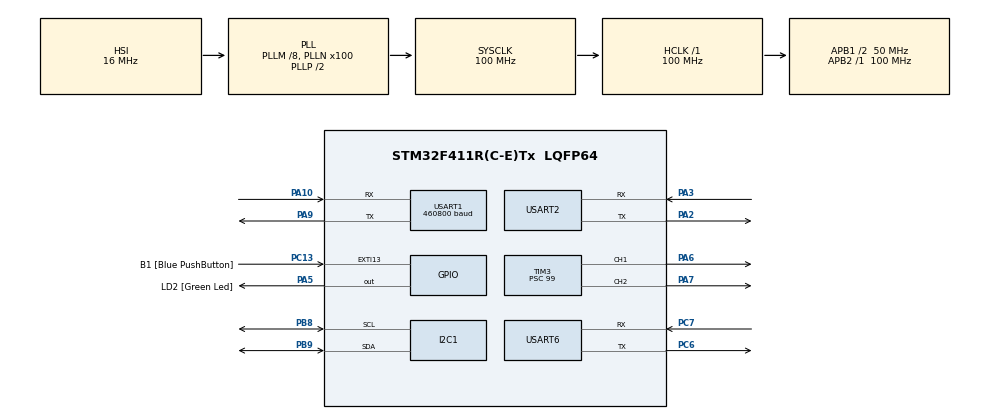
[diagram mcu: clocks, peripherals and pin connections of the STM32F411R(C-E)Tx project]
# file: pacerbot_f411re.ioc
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Dma.Request0=USART1_RX
Dma.Request1=USART1_TX
Dma.Request2=USART6_RX
Dma.Request3=USART6_TX
Dma.USART1_RX.0.Direction=DMA_PERIPH_TO_MEMORY
Dma.USART1_RX.0.FIFOMode=DMA_FIFOMODE_DISABLE
Dma.USART1_RX.0.Instance=DMA2_Stream2
Dma.USART1_RX.0.MemDataAlignment=DMA_MDATAALIGN_BYTE
Dma.USART1_RX.0.MemInc=DMA_MINC_ENABLE
Dma.USART1_RX.0.Mode=DMA_CIRCULAR
Dma.USART1_RX.0.PeriphDataAlignment=DMA_PDATAALIGN_BYTE
Dma.USART1_RX.0.PeriphInc=DMA_PINC_DISABLE
Dma.USART1_RX.0.Priority=DMA_PRIORITY_HIGH
Dma.USART1_TX.1.Direction=DMA_MEMORY_TO_PERIPH
Dma.USART1_TX.1.FIFOMode=DMA_FIFOMODE_DISABLE
Dma.USART1_TX.1.Instance=DMA2_Stream7
Dma.USART1_TX.1.MemDataAlignment=DMA_MDATAALIGN_BYTE
Dma.USART1_TX.1.MemInc=DMA_MINC_ENABLE
Dma.USART1_TX.1.Mode=DMA_NORMAL
Dma.USART1_TX.1.PeriphDataAlignment=DMA_PDATAALIGN_BYTE
Dma.USART1_TX.1.PeriphInc=DMA_PINC_DISABLE
Dma.USART1_TX.1.Priority=DMA_PRIORITY_LOW
Dma.USART6_RX.2.Direction=DMA_PERIPH_TO_MEMORY
Dma.USART6_RX.2.FIFOMode=DMA_FIFOMODE_DISABLE
Dma.USART6_RX.2.Instance=DMA2_Stream1
Dma.USART6_RX.2.MemDataAlignment=DMA_MDATAALIGN_BYTE
Dma.USART6_RX.2.MemInc=DMA_MINC_ENABLE
Dma.USART6_RX.2.Mode=DMA_CIRCULAR
Dma.USART6_RX.2.PeriphDataAlignment=DMA_PDATAALIGN_BYTE
Dma.USART6_RX.2.PeriphInc=DMA_PINC_DISABLE
Dma.USART6_RX.2.Priority=DMA_PRIORITY_MEDIUM
Dma.USART6_TX.3.Direction=DMA_MEMORY_TO_PERIPH
Dma.USART6_TX.3.FIFOMode=DMA_FIFOMODE_DISABLE
Dma.USART6_TX.3.Instance=DMA2_Stream6
Dma.USART6_TX.3.MemDataAlignment=DMA_MDATAALIGN_BYTE
Dma.USART6_TX.3.MemInc=DMA_MINC_ENABLE
Dma.USART6_TX.3.Mode=DMA_NORMAL
Dma.USART6_TX.3.PeriphDataAlignment=DMA_PDATAALIGN_BYTE
Dma.USART6_TX.3.PeriphInc=DMA_PINC_DISABLE
Dma.USART6_TX.3.Priority=DMA_PRIORITY_LOW
FREERTOS.Tasks01=defaultTask,8,1024,StartDefaultTask,Default,NULL,Dynamic,NULL,NULL
FREERTOS.configENABLE_FPU=1
FREERTOS.configTOTAL_HEAP_SIZE=64000
Mcu.Family=STM32F4
Mcu.Name=STM32F411R(C-E)Tx
Mcu.Package=LQFP64
NVIC.DMA2_Stream1_IRQn=true\:5\:0\:false\:false\:true\:true\:false\:true\:true
NVIC.DMA2_Stream2_IRQn=true\:5\:0\:false\:false\:true\:true\:false\:true\:true
NVIC.DMA2_Stream6_IRQn=true\:5\:0\:false\:false\:true\:true\:false\:true\:true
NVIC.DMA2_Stream7_IRQn=true\:5\:0\:false\:false\:true\:true\:false\:true\:true
NVIC.PriorityGroup=NVIC_PRIORITYGROUP_4
NVIC.TIM1_UP_TIM10_IRQn=true\:15\:0\:false\:false\:true\:false\:false\:true\:true
NVIC.TimeBase=TIM1_UP_TIM10_IRQn
NVIC.TimeBaseIP=TIM1
NVIC.USART1_IRQn=true\:5\:0\:false\:false\:true\:true\:true\:true\:true
NVIC.USART2_IRQn=true\:5\:0\:false\:false\:true\:true\:true\:true\:true
NVIC.USART6_IRQn=true\:5\:0\:false\:false\:true\:true\:true\:true\:true
PA10.Mode=Asynchronous
PA10.Signal=USART1_RX
PA13.GPIO_Label=TMS
PA13.Mode=Serial_Wire
PA13.Signal=SYS_JTMS-SWDIO
PA14.GPIO_Label=TCK
PA14.Mode=Serial_Wire
PA14.Signal=SYS_JTCK-SWCLK
PA2.Mode=Asynchronous
PA2.Signal=USART2_TX
PA3.Mode=Asynchronous
PA3.Signal=USART2_RX
PA5.GPIO_Label=LD2 [Green Led]
PA5.Signal=GPIO_Output
PA6.Signal=S_TIM3_CH1
PA7.Signal=S_TIM3_CH2
PA9.Mode=Asynchronous
PA9.Signal=USART1_TX
PB3.GPIO_Label=SWO
PB3.Signal=SYS_JTDO-SWO
PB8.Mode=I2C
PB8.Signal=I2C1_SCL
PB9.Mode=I2C
PB9.Signal=I2C1_SDA
PC13-ANTI_TAMP.GPIO_Label=B1 [Blue PushButton]
PC13-ANTI_TAMP.GPIO_ModeDefaultEXTI=GPIO_MODE_IT_FALLING
PC13-ANTI_TAMP.Signal=GPXTI13
PC14-OSC32_IN.Mode=LSE-External-Oscillator
PC14-OSC32_IN.Signal=RCC_OSC32_IN
PC15-OSC32_OUT.Mode=LSE-External-Oscillator
PC15-OSC32_OUT.Signal=RCC_OSC32_OUT
PC6.Mode=Asynchronous
PC6.Signal=USART6_TX
PC7.Mode=Asynchronous
PC7.Signal=USART6_RX
PH0\ -\ OSC_IN.Mode=HSE-External-Clock-Source
PH0\ -\ OSC_IN.Signal=RCC_OSC_IN
PH1\ -\ OSC_OUT.Mode=HSE-External-Clock-Source
PH1\ -\ OSC_OUT.Signal=RCC_OSC_OUT
ProjectManager.HeapSize=0x200
ProjectManager.StackSize=0x400
ProjectManager.TargetToolchain=CMake
RCC.48MHZClocksFreq_Value=50000000
RCC.AHBFreq_Value=100000000
RCC.APB1CLKDivider=RCC_HCLK_DIV2
RCC.APB1Freq_Value=50000000
RCC.APB1TimFreq_Value=100000000
RCC.APB2Freq_Value=100000000
RCC.APB2TimFreq_Value=100000000
RCC.CortexFreq_Value=100000000
RCC.FLatency-AdvancedSettings=FLASH_LATENCY_3
RCC.HCLKFreq_Value=100000000
RCC.HSE_VALUE=8000000
RCC.HSI_VALUE=16000000
RCC.PLLM=8
RCC.PLLN=100
RCC.SYSCLKFreq_VALUE=100000000
RCC.SYSCLKSource=RCC_SYSCLKSOURCE_PLLCLK
RCC.VCOOutputFreq_Value=200000000
SH.S_TIM3_CH1.0=TIM3_CH1,PWM Generation1 CH1
SH.S_TIM3_CH2.0=TIM3_CH2,PWM Generation2 CH2
TIM3.AutoReloadPreload=TIM_AUTORELOAD_PRELOAD_ENABLE
TIM3.Channel-PWM\ Generation1\ CH1=TIM_CHANNEL_1
TIM3.Channel-PWM\ Generation2\ CH2=TIM_CHANNEL_2
TIM3.Period=19999
TIM3.Prescaler=99
TIM3.Pulse-PWM\ Generation1\ CH1=1500
USART1.BaudRate=460800
USART1.VirtualMode=VM_ASYNC
USART2.VirtualMode=VM_ASYNC
USART6.VirtualMode=VM_ASYNC
VP_FREERTOS_VS_CMSIS_V2.Mode=CMSIS_V2
VP_SYS_VS_tim1.Mode=TIM1
board=NUCLEO-F411RE

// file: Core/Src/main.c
/* USER CODE BEGIN Header */
/**
 ******************************************************************************
 * @file           : main.c
 * @brief          : Main program body
 ******************************************************************************
 * @attention
 *
 * Copyright (c) 2025 STMicroelectronics.
 * All rights reserved.
 *
 * This software is licensed under terms that can be found in the LICENSE file
 * in the root directory of this software component.
 * If no LICENSE file comes with this software, it is provided AS-IS.
 *
 ******************************************************************************
 */
/* USER CODE END Header */
#include "main.h"
#include "cmsis_os.h"

/* USER CODE BEGIN Includes */
#include "app/app_main.h"

#include <stdio.h>
#include <string.h>
#include <unistd.h>
/* USER CODE END Includes */

/* USER CODE BEGIN PD */
#define IMU_ADDRESS  0x68
#define WHO_AM_I     0x75
#define ACCEL_CONFIG 0x1C
#define ACCEL_XOUT_H 0x3B
#define ACCEL_YOUT_H 0x3D
#define GYRO_XOUT_H  0x43

/* USER CODE END PD */

I2C_HandleTypeDef hi2c1;

TIM_HandleTypeDef htim3;

UART_HandleTypeDef huart1;
UART_HandleTypeDef huart2;
UART_HandleTypeDef huart6;
DMA_HandleTypeDef hdma_usart1_rx;
DMA_HandleTypeDef hdma_usart1_tx;
DMA_HandleTypeDef hdma_usart6_rx;
DMA_HandleTypeDef hdma_usart6_tx;

/* Definitions for defaultTask */
osThreadId_t defaultTaskHandle;
const osThreadAttr_t defaultTask_attributes = {
  .name = "defaultTask",
  .stack_size = 1024 * 4,
  .priority = (osPriority_t) osPriorityLow,
};

void SystemClock_Config(void);
static void MX_GPIO_Init(void);
static void MX_DMA_Init(void);
static void MX_I2C1_Init(void);
static void MX_USART1_UART_Init(void);
static void MX_USART2_UART_Init(void);
static void MX_TIM3_Init(void);
static void MX_USART6_UART_Init(void);
void StartDefaultTask(void *argument);

int main(void)
{

  /* MCU Configuration--------------------------------------------------------*/

  /* Reset of all peripherals, Initializes the Flash interface and the Systick. */
  HAL_Init();

  /* Configure the system clock */
  SystemClock_Config();

  /* Initialize all configured peripherals */
  MX_GPIO_Init();
  MX_DMA_Init();
  MX_I2C1_Init();
  MX_USART1_UART_Init();
  MX_USART2_UART_Init();
  MX_TIM3_Init();
  MX_USART6_UART_Init();
  /* USER CODE BEGIN 2 */
    setvbuf(stdout, NULL, _IONBF, 0);
    printf("BOOT: hello on USART2\n");

  /* USER CODE END 2 */

  /* Init scheduler */
  osKernelInitialize();

  /* Create the thread(s) */
  /* creation of defaultTask */
  defaultTaskHandle = osThreadNew(StartDefaultTask, NULL, &defaultTask_attributes);

  /* Start scheduler */
  osKernelStart();

  /* We should never get here as control is now taken by the scheduler */

  /* Infinite loop */
    while (1) {

    }
}

void SystemClock_Config(void)
{
  RCC_OscInitTypeDef RCC_OscInitStruct = {0};
  RCC_ClkInitTypeDef RCC_ClkInitStruct = {0};

  /** Configure the main internal regulator output voltage
  */
  __HAL_RCC_PWR_CLK_ENABLE();
  __HAL_PWR_VOLTAGESCALING_CONFIG(PWR_REGULATOR_VOLTAGE_SCALE1);

  /** Initializes the RCC Oscillators according to the specified parameters
  * in the RCC_OscInitTypeDef structure.
  */
  RCC_OscInitStruct.OscillatorType = RCC_OSCILLATORTYPE_HSI;
  RCC_OscInitStruct.HSIState = RCC_HSI_ON;
  RCC_OscInitStruct.HSICalibrationValue = RCC_HSICALIBRATION_DEFAULT;
  RCC_OscInitStruct.PLL.PLLState = RCC_PLL_ON;
  RCC_OscInitStruct.PLL.PLLSource = RCC_PLLSOURCE_HSI;
  RCC_OscInitStruct.PLL.PLLM = 8;
  RCC_OscInitStruct.PLL.PLLN = 100;
  RCC_OscInitStruct.PLL.PLLP = RCC_PLLP_DIV2;
  RCC_OscInitStruct.PLL.PLLQ = 4;
  if (HAL_RCC_OscConfig(&RCC_OscInitStruct) != HAL_OK)
  {
    Error_Handler();
  }

  /** Initializes the CPU, AHB and APB buses clocks
  */
  RCC_ClkInitStruct.ClockType = RCC_CLOCKTYPE_HCLK|RCC_CLOCKTYPE_SYSCLK
                              |RCC_CLOCKTYPE_PCLK1|RCC_CLOCKTYPE_PCLK2;
  RCC_ClkInitStruct.SYSCLKSource = RCC_SYSCLKSOURCE_PLLCLK;
  RCC_ClkInitStruct.AHBCLKDivider = RCC_SYSCLK_DIV1;
  RCC_ClkInitStruct.APB1CLKDivider = RCC_HCLK_DIV2;
  RCC_ClkInitStruct.APB2CLKDivider = RCC_HCLK_DIV1;

  if (HAL_RCC_ClockConfig(&RCC_ClkInitStruct, FLASH_LATENCY_3) != HAL_OK)
  {
    Error_Handler();
  }
}

static void MX_I2C1_Init(void)
{

  hi2c1.Instance = I2C1;
  hi2c1.Init.ClockSpeed = 100000;
  hi2c1.Init.DutyCycle = I2C_DUTYCYCLE_2;
  hi2c1.Init.OwnAddress1 = 0;
  hi2c1.Init.AddressingMode = I2C_ADDRESSINGMODE_7BIT;
  hi2c1.Init.DualAddressMode = I2C_DUALADDRESS_DISABLE;
  hi2c1.Init.OwnAddress2 = 0;
  hi2c1.Init.GeneralCallMode = I2C_GENERALCALL_DISABLE;
  hi2c1.Init.NoStretchMode = I2C_NOSTRETCH_DISABLE;
  if (HAL_I2C_Init(&hi2c1) != HAL_OK)
  {
    Error_Handler();
  }

}

static void MX_TIM3_Init(void)
{

  TIM_MasterConfigTypeDef sMasterConfig = {0};
  TIM_OC_InitTypeDef sConfigOC = {0};

  htim3.Instance = TIM3;
  htim3.Init.Prescaler = 99;
  htim3.Init.CounterMode = TIM_COUNTERMODE_UP;
  htim3.Init.Period = 19999;
  htim3.Init.ClockDivision = TIM_CLOCKDIVISION_DIV1;
  htim3.Init.AutoReloadPreload = TIM_AUTORELOAD_PRELOAD_ENABLE;
  if (HAL_TIM_PWM_Init(&htim3) != HAL_OK)
  {
    Error_Handler();
  }
  sMasterConfig.MasterOutputTrigger = TIM_TRGO_RESET;
  sMasterConfig.MasterSlaveMode = TIM_MASTERSLAVEMODE_DISABLE;
  if (HAL_TIMEx_MasterConfigSynchronization(&htim3, &sMasterConfig) != HAL_OK)
  {
    Error_Handler();
  }
  sConfigOC.OCMode = TIM_OCMODE_PWM1;
  sConfigOC.Pulse = 1500;
  sConfigOC.OCPolarity = TIM_OCPOLARITY_HIGH;
  sConfigOC.OCFastMode = TIM_OCFAST_DISABLE;
  if (HAL_TIM_PWM_ConfigChannel(&htim3, &sConfigOC, TIM_CHANNEL_1) != HAL_OK)
  {
    Error_Handler();
  }
  sConfigOC.Pulse = 0;
  if (HAL_TIM_PWM_ConfigChannel(&htim3, &sConfigOC, TIM_CHANNEL_2) != HAL_OK)
  {
    Error_Handler();
  }
  HAL_TIM_MspPostInit(&htim3);

}

static void MX_USART1_UART_Init(void)
{

  huart1.Instance = USART1;
  huart1.Init.BaudRate = 460800;
  huart1.Init.WordLength = UART_WORDLENGTH_8B;
  huart1.Init.StopBits = UART_STOPBITS_1;
  huart1.Init.Parity = UART_PARITY_NONE;
  huart1.Init.Mode = UART_MODE_TX_RX;
  huart1.Init.HwFlowCtl = UART_HWCONTROL_NONE;
  huart1.Init.OverSampling = UART_OVERSAMPLING_16;
  if (HAL_UART_Init(&huart1) != HAL_OK)
  {
    Error_Handler();
  }

}

static void MX_USART2_UART_Init(void)
{

  huart2.Instance = USART2;
  huart2.Init.BaudRate = 115200;
  huart2.Init.WordLength = UART_WORDLENGTH_8B;
  huart2.Init.StopBits = UART_STOPBITS_1;
  huart2.Init.Parity = UART_PARITY_NONE;
  huart2.Init.Mode = UART_MODE_TX_RX;
  huart2.Init.HwFlowCtl = UART_HWCONTROL_NONE;
  huart2.Init.OverSampling = UART_OVERSAMPLING_16;
  if (HAL_UART_Init(&huart2) != HAL_OK)
  {
    Error_Handler();
  }

}

static void MX_USART6_UART_Init(void)
{

  huart6.Instance = USART6;
  huart6.Init.BaudRate = 115200;
  huart6.Init.WordLength = UART_WORDLENGTH_8B;
  huart6.Init.StopBits = UART_STOPBITS_1;
  huart6.Init.Parity = UART_PARITY_NONE;
  huart6.Init.Mode = UART_MODE_TX_RX;
  huart6.Init.HwFlowCtl = UART_HWCONTROL_NONE;
  huart6.Init.OverSampling = UART_OVERSAMPLING_16;
  if (HAL_UART_Init(&huart6) != HAL_OK)
  {
    Error_Handler();
  }

}

static void MX_DMA_Init(void)
{

  /* DMA controller clock enable */
  __HAL_RCC_DMA2_CLK_ENABLE();

  /* DMA interrupt init */
  /* DMA2_Stream1_IRQn interrupt configuration */
  HAL_NVIC_SetPriority(DMA2_Stream1_IRQn, 5, 0);
  HAL_NVIC_EnableIRQ(DMA2_Stream1_IRQn);
  /* DMA2_Stream2_IRQn interrupt configuration */
  HAL_NVIC_SetPriority(DMA2_Stream2_IRQn, 5, 0);
  HAL_NVIC_EnableIRQ(DMA2_Stream2_IRQn);
  /* DMA2_Stream6_IRQn interrupt configuration */
  HAL_NVIC_SetPriority(DMA2_Stream6_IRQn, 5, 0);
  HAL_NVIC_EnableIRQ(DMA2_Stream6_IRQn);
  /* DMA2_Stream7_IRQn interrupt configuration */
  HAL_NVIC_SetPriority(DMA2_Stream7_IRQn, 5, 0);
  HAL_NVIC_EnableIRQ(DMA2_Stream7_IRQn);

}

static void MX_GPIO_Init(void)
{
  GPIO_InitTypeDef GPIO_InitStruct = {0};

  /* GPIO Ports Clock Enable */
  __HAL_RCC_GPIOC_CLK_ENABLE();
  __HAL_RCC_GPIOH_CLK_ENABLE();
  __HAL_RCC_GPIOA_CLK_ENABLE();
  __HAL_RCC_GPIOB_CLK_ENABLE();

  /*Configure GPIO pin Output Level */
  HAL_GPIO_WritePin(LD2_GPIO_Port, LD2_Pin, GPIO_PIN_RESET);

  /*Configure GPIO pin : B1_Pin */
  GPIO_InitStruct.Pin = B1_Pin;
  GPIO_InitStruct.Mode = GPIO_MODE_IT_FALLING;
  GPIO_InitStruct.Pull = GPIO_NOPULL;
  HAL_GPIO_Init(B1_GPIO_Port, &GPIO_InitStruct);

  /*Configure GPIO pin : LD2_Pin */
  GPIO_InitStruct.Pin = LD2_Pin;
  GPIO_InitStruct.Mode = GPIO_MODE_OUTPUT_PP;
  GPIO_InitStruct.Pull = GPIO_NOPULL;
  GPIO_InitStruct.Speed = GPIO_SPEED_FREQ_LOW;
  HAL_GPIO_Init(LD2_GPIO_Port, &GPIO_InitStruct);

}

void StartDefaultTask(void *argument)
{
  /* USER CODE BEGIN 5 */
    app_main();

    /* Infinite loop */
    for (;;) {
        osDelay(1);
    }
  /* USER CODE END 5 */
}

void HAL_TIM_PeriodElapsedCallback(TIM_HandleTypeDef *htim)
{
  if (htim->Instance == TIM1)
  {
    HAL_IncTick();
  }
}

void Error_Handler(void)
{
    __disable_irq();
    while (1) {
    }
}
